VERSION "cluster-private-0.2"

NS_ :

BS_:

BU_: GAUGES DISPLAY

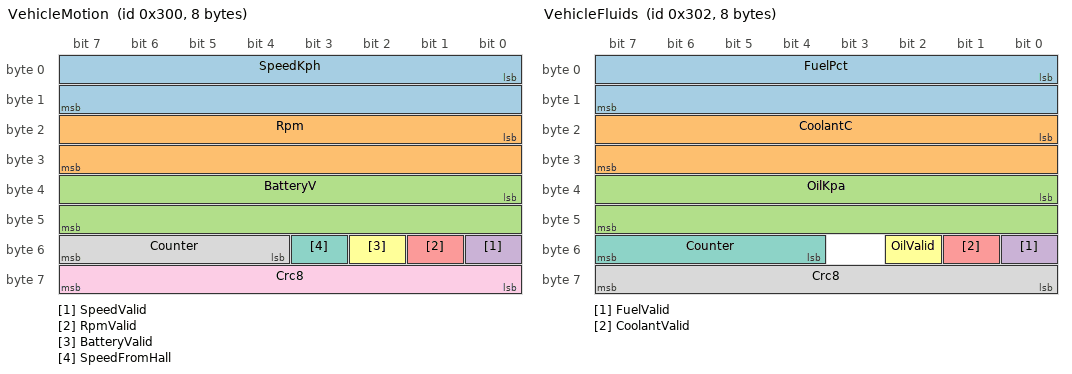
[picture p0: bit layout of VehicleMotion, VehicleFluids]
BO_ 768 VehicleMotion: 8 GAUGES
 SG_ SpeedKph : 0|16@1+ (0.1,0.0) [0.0|400.0] "km/h" DISPLAY
 SG_ Rpm : 16|16@1+ (1.0,0.0) [0.0|12000.0] "rpm" DISPLAY
 SG_ BatteryV : 32|16@1+ (0.01,0.0) [0.0|20.0] "V" DISPLAY
 SG_ SpeedValid : 48|1@1+ (1.0,0.0) [0.0|1.0] "" DISPLAY
 SG_ RpmValid : 49|1@1+ (1.0,0.0) [0.0|1.0] "" DISPLAY
 SG_ BatteryValid : 50|1@1+ (1.0,0.0) [0.0|1.0] "" DISPLAY
 SG_ SpeedFromHall : 51|1@1+ (1.0,0.0) [0.0|1.0] "" DISPLAY
 SG_ Counter : 52|4@1+ (1.0,0.0) [0.0|15.0] "" DISPLAY
 SG_ Crc8 : 56|8@1+ (1.0,0.0) [0.0|255.0] "" DISPLAY

BO_ 770 VehicleFluids: 8 GAUGES
 SG_ FuelPct : 0|16@1+ (0.01,0.0) [0.0|100.0] "%" DISPLAY
 SG_ CoolantC : 16|16@1- (0.1,0.0) [-40.0|150.0] "degC" DISPLAY
 SG_ OilKpa : 32|16@1+ (0.1,0.0) [0.0|1000.0] "kPa" DISPLAY
 SG_ FuelValid : 48|1@1+ (1.0,0.0) [0.0|1.0] "" DISPLAY
 SG_ CoolantValid : 49|1@1+ (1.0,0.0) [0.0|1.0] "" DISPLAY
 SG_ OilValid : 50|1@1+ (1.0,0.0) [0.0|1.0] "" DISPLAY
 SG_ Counter : 52|4@1+ (1.0,0.0) [0.0|15.0] "" DISPLAY
 SG_ Crc8 : 56|8@1+ (1.0,0.0) [0.0|255.0] "" DISPLAY

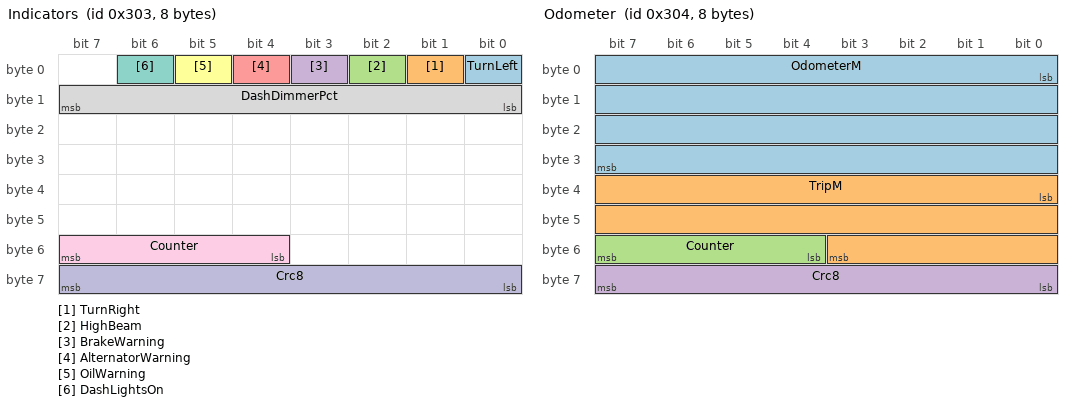
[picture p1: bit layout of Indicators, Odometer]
BO_ 771 Indicators: 8 GAUGES
 SG_ TurnLeft : 0|1@1+ (1.0,0.0) [0.0|1.0] "" DISPLAY
 SG_ TurnRight : 1|1@1+ (1.0,0.0) [0.0|1.0] "" DISPLAY
 SG_ HighBeam : 2|1@1+ (1.0,0.0) [0.0|1.0] "" DISPLAY
 SG_ BrakeWarning : 3|1@1+ (1.0,0.0) [0.0|1.0] "" DISPLAY
 SG_ AlternatorWarning : 4|1@1+ (1.0,0.0) [0.0|1.0] "" DISPLAY
 SG_ OilWarning : 5|1@1+ (1.0,0.0) [0.0|1.0] "" DISPLAY
 SG_ DashLightsOn : 6|1@1+ (1.0,0.0) [0.0|1.0] "" DISPLAY
 SG_ DashDimmerPct : 8|8@1+ (1.0,0.0) [0.0|100.0] "%" DISPLAY
 SG_ Counter : 52|4@1+ (1.0,0.0) [0.0|15.0] "" DISPLAY
 SG_ Crc8 : 56|8@1+ (1.0,0.0) [0.0|255.0] "" DISPLAY

BO_ 769 GaugesStatus: 8 GAUGES
 SG_ FwMajor : 0|8@1+ (1.0,0.0) [0.0|255.0] "" DISPLAY
 SG_ FwMinor : 8|8@1+ (1.0,0.0) [0.0|255.0] "" DISPLAY
 SG_ FuelSenderOpen : 16|1@1+ (1.0,0.0) [0.0|1.0] "" DISPLAY
 SG_ OilSenderOpen : 17|1@1+ (1.0,0.0) [0.0|1.0] "" DISPLAY
 SG_ TempSenderOpen : 18|1@1+ (1.0,0.0) [0.0|1.0] "" DISPLAY
 SG_ CarBusActive : 19|1@1+ (1.0,0.0) [0.0|1.0] "" DISPLAY
 SG_ FuelFromCar : 20|1@1+ (1.0,0.0) [0.0|1.0] "" DISPLAY
 SG_ CoolantFromCar : 21|1@1+ (1.0,0.0) [0.0|1.0] "" DISPLAY
 SG_ OilFromCar : 22|1@1+ (1.0,0.0) [0.0|1.0] "" DISPLAY
 SG_ BatteryFromCar : 23|1@1+ (1.0,0.0) [0.0|1.0] "" DISPLAY
 SG_ ActiveProfile : 24|8@1+ (1.0,0.0) [0.0|255.0] "" DISPLAY
 SG_ DisplayOffline : 32|1@1+ (1.0,0.0) [0.0|1.0] "" DISPLAY
 SG_ RpmFromTach : 33|1@1+ (1.0,0.0) [0.0|1.0] "" DISPLAY
 SG_ NvStorageOk : 34|1@1+ (1.0,0.0) [0.0|1.0] "" DISPLAY
 SG_ ResetCause : 40|8@1+ (1.0,0.0) [0.0|255.0] "" DISPLAY
 SG_ LimpLevel : 48|2@1+ (1.0,0.0) [0.0|3.0] "" DISPLAY
 SG_ QuarantineMask : 50|6@1+ (1.0,0.0) [0.0|63.0] "" DISPLAY
 SG_ WatchdogResets : 56|8@1+ (1.0,0.0) [0.0|255.0] "" DISPLAY

BO_ 772 Odometer: 8 GAUGES
 SG_ OdometerM : 0|32@1+ (1.0,0.0) [0.0|4.29497e+09] "m" DISPLAY
 SG_ TripM : 32|20@1+ (1.0,0.0) [0.0|1.04858e+06] "m" DISPLAY
 SG_ Counter : 52|4@1+ (1.0,0.0) [0.0|15.0] "" DISPLAY
 SG_ Crc8 : 56|8@1+ (1.0,0.0) [0.0|255.0] "" DISPLAY

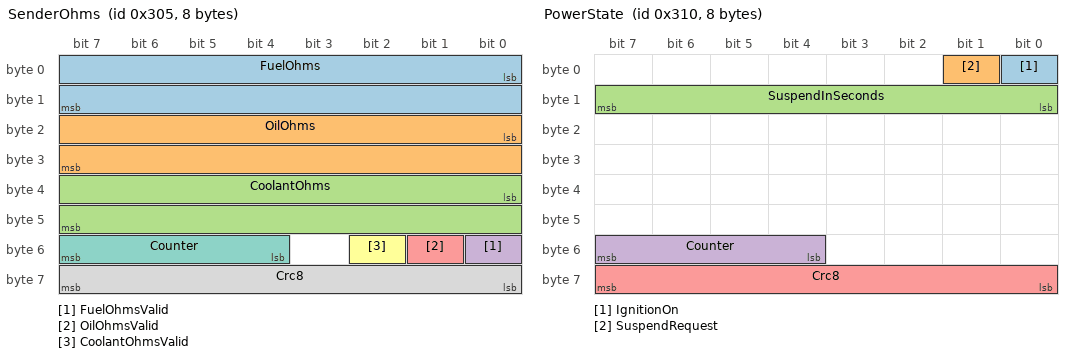
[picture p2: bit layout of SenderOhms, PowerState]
BO_ 773 SenderOhms: 8 GAUGES
 SG_ FuelOhms : 0|16@1+ (0.1,0.0) [0.0|6553.5] "ohm" DISPLAY
 SG_ OilOhms : 16|16@1+ (0.1,0.0) [0.0|6553.5] "ohm" DISPLAY
 SG_ CoolantOhms : 32|16@1+ (0.1,0.0) [0.0|6553.5] "ohm" DISPLAY
 SG_ FuelOhmsValid : 48|1@1+ (1.0,0.0) [0.0|1.0] "" DISPLAY
 SG_ OilOhmsValid : 49|1@1+ (1.0,0.0) [0.0|1.0] "" DISPLAY
 SG_ CoolantOhmsValid : 50|1@1+ (1.0,0.0) [0.0|1.0] "" DISPLAY
 SG_ Counter : 52|4@1+ (1.0,0.0) [0.0|15.0] "" DISPLAY
 SG_ Crc8 : 56|8@1+ (1.0,0.0) [0.0|255.0] "" DISPLAY

BO_ 784 PowerState: 8 GAUGES
 SG_ IgnitionOn : 0|1@1+ (1.0,0.0) [0.0|1.0] "" DISPLAY
 SG_ SuspendRequest : 1|1@1+ (1.0,0.0) [0.0|1.0] "" DISPLAY
 SG_ SuspendInSeconds : 8|8@1+ (1.0,0.0) [0.0|255.0] "s" DISPLAY
 SG_ Counter : 52|4@1+ (1.0,0.0) [0.0|15.0] "" DISPLAY
 SG_ Crc8 : 56|8@1+ (1.0,0.0) [0.0|255.0] "" DISPLAY

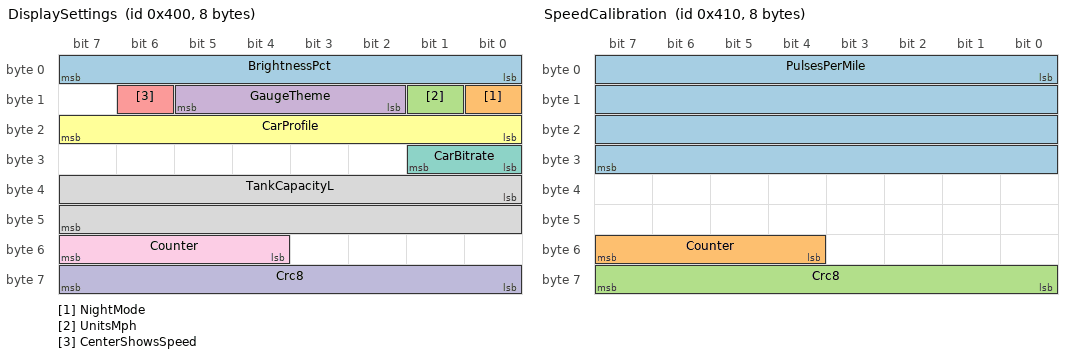
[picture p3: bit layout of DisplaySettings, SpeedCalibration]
BO_ 1024 DisplaySettings: 8 DISPLAY
 SG_ BrightnessPct : 0|8@1+ (1.0,0.0) [0.0|100.0] "%" GAUGES
 SG_ NightMode : 8|1@1+ (1.0,0.0) [0.0|1.0] "" GAUGES
 SG_ UnitsMph : 9|1@1+ (1.0,0.0) [0.0|1.0] "" GAUGES
 SG_ GaugeTheme : 10|4@1+ (1.0,0.0) [0.0|15.0] "" GAUGES
 SG_ CenterShowsSpeed : 14|1@1+ (1.0,0.0) [0.0|1.0] "" GAUGES
 SG_ CarProfile : 16|8@1+ (1.0,0.0) [0.0|255.0] "" GAUGES
 SG_ CarBitrate : 24|2@1+ (1.0,0.0) [0.0|3.0] "" GAUGES
 SG_ TankCapacityL : 32|16@1+ (0.1,0.0) [0.0|200.0] "L" GAUGES
 SG_ Counter : 52|4@1+ (1.0,0.0) [0.0|15.0] "" GAUGES
 SG_ Crc8 : 56|8@1+ (1.0,0.0) [0.0|255.0] "" GAUGES

BO_ 1040 SpeedCalibration: 8 DISPLAY
 SG_ PulsesPerMile : 0|32@1+ (1.0,0.0) [100.0|200000.0] "" GAUGES
 SG_ Counter : 52|4@1+ (1.0,0.0) [0.0|15.0] "" GAUGES
 SG_ Crc8 : 56|8@1+ (1.0,0.0) [0.0|255.0] "" GAUGES

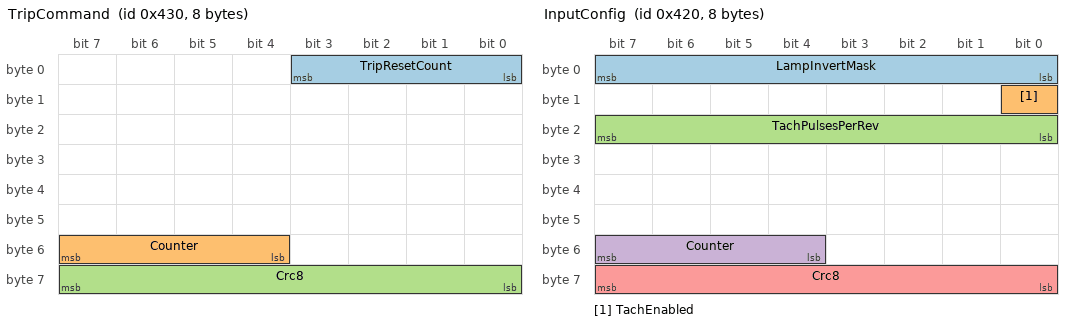
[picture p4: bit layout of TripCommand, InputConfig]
BO_ 1072 TripCommand: 8 DISPLAY
 SG_ TripResetCount : 0|4@1+ (1.0,0.0) [0.0|15.0] "" GAUGES
 SG_ Counter : 52|4@1+ (1.0,0.0) [0.0|15.0] "" GAUGES
 SG_ Crc8 : 56|8@1+ (1.0,0.0) [0.0|255.0] "" GAUGES

BO_ 1056 InputConfig: 8 DISPLAY
 SG_ LampInvertMask : 0|8@1+ (1.0,0.0) [0.0|63.0] "" GAUGES
 SG_ TachEnabled : 8|1@1+ (1.0,0.0) [0.0|1.0] "" GAUGES
 SG_ TachPulsesPerRev : 16|8@1+ (1.0,0.0) [1.0|16.0] "" GAUGES
 SG_ Counter : 52|4@1+ (1.0,0.0) [0.0|15.0] "" GAUGES
 SG_ Crc8 : 56|8@1+ (1.0,0.0) [0.0|255.0] "" GAUGES

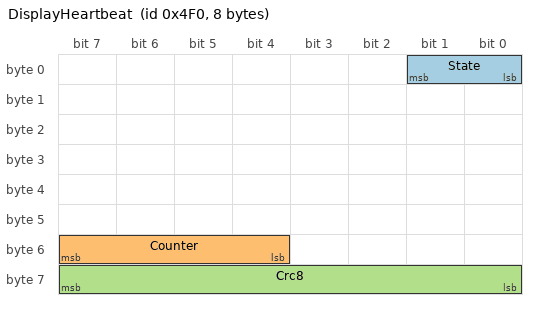
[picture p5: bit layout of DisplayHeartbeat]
BO_ 1264 DisplayHeartbeat: 8 DISPLAY
 SG_ State : 0|2@1+ (1.0,0.0) [0.0|3.0] "" GAUGES
 SG_ Counter : 52|4@1+ (1.0,0.0) [0.0|15.0] "" GAUGES
 SG_ Crc8 : 56|8@1+ (1.0,0.0) [0.0|255.0] "" GAUGES

CM_ BO_ 768 "Consolidated motion data, chosen by gauges/ from the Hall input and the car bus.";
CM_ BO_ 770 "Consolidated fluid data: ECU value if fresh, else local sender.";
CM_ BO_ 771 "Indicator-lamp states from the six 12 V lamp inputs on gauges/ (1 = lamp on after the per-channel polarity setting), sent every 100 ms and on every change.";
CM_ BO_ 769 "Health, identity and where each value currently comes from.";
CM_ BO_ 772 "Distance counters kept by gauges/ (they survive power loss there, see software/gauges-fw/README.md). Metres; the display converts to miles or km. The trip meter is 20 bits, so it wraps at 1048.575 km.";
CM_ BO_ 773 "Live resistance of the three resistive senders, for measuring their curves in the car (docs/sender-calibration.md): read it off the display at known levels and generate software/gauges-fw/src/sender_curves.c from the readings. Added 2026-10-18.";
CM_ BO_ 784 "Ignition and sleep coordination; also sent on every change.";
CM_ BO_ 1024 "Persistent settings owned by Android; sent on change and every second. gauges/ keeps the last copy in flash.";
CM_ BO_ 1040 "Pulses per mile for the speed input, Hall or VR (AutoMeter 16-pulse sender at 1000 rev/mile = 16000; a Ford VSS is commonly quoted at 8000).";
CM_ BO_ 1072 "Trip meter reset. gauges/ resets the trip meter when TripResetCount differs from the last value it saw (so a repeated or lost frame resets it exactly once per button press); the first frame after power-up only records the value.";
CM_ BO_ 1056 "Per-input options for the lamp and tach inputs on gauges/. A lamp wired ground-switched (the DNP pull-up fitted) idles high, so its bit here is set to invert it.";
CM_ BO_ 1264 "Liveness plus coarse state; gauges/ marks the display offline if this stops.";

BA_DEF_ BO_ "GenMsgCycleTime" INT 0 65535;
BA_DEF_DEF_ "GenMsgCycleTime" 0;
BA_ "GenMsgCycleTime" BO_ 768 50;
BA_ "GenMsgCycleTime" BO_ 770 100;
BA_ "GenMsgCycleTime" BO_ 771 100;
BA_ "GenMsgCycleTime" BO_ 769 1000;
BA_ "GenMsgCycleTime" BO_ 772 1000;
BA_ "GenMsgCycleTime" BO_ 773 1000;
BA_ "GenMsgCycleTime" BO_ 784 500;
BA_ "GenMsgCycleTime" BO_ 1024 1000;
BA_ "GenMsgCycleTime" BO_ 1040 1000;
BA_ "GenMsgCycleTime" BO_ 1072 1000;
BA_ "GenMsgCycleTime" BO_ 1056 1000;
BA_ "GenMsgCycleTime" BO_ 1264 1000;
